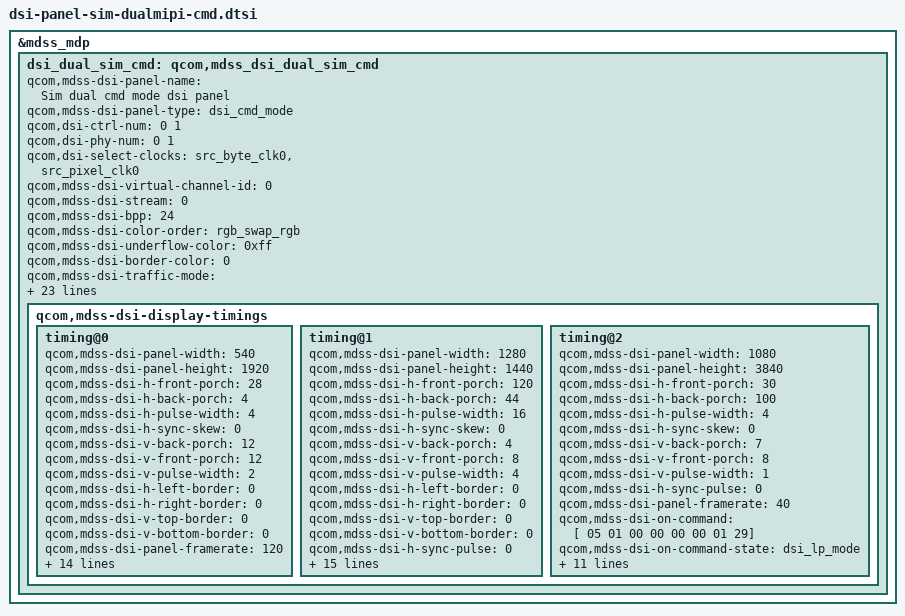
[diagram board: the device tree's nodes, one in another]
&mdss_mdp {
	dsi_dual_sim_cmd: qcom,mdss_dsi_dual_sim_cmd {
		qcom,mdss-dsi-panel-name = "Sim dual cmd mode dsi panel";
		qcom,mdss-dsi-panel-type = "dsi_cmd_mode";

		qcom,dsi-ctrl-num = <0 1>;
		qcom,dsi-phy-num = <0 1>;
		qcom,dsi-select-clocks = "src_byte_clk0", "src_pixel_clk0";

		qcom,mdss-dsi-virtual-channel-id = <0>;
		qcom,mdss-dsi-stream = <0>;
		qcom,mdss-dsi-bpp = <24>;
		qcom,mdss-dsi-color-order = "rgb_swap_rgb";
		qcom,mdss-dsi-underflow-color = <0xff>;
		qcom,mdss-dsi-border-color = <0>;
		qcom,mdss-dsi-traffic-mode = "non_burst_sync_event";
		qcom,mdss-dsi-bllp-eof-power-mode;
		qcom,mdss-dsi-bllp-power-mode;
		qcom,cmd-sync-wait-broadcast;
		qcom,mdss-dsi-lane-0-state;
		qcom,mdss-dsi-lane-1-state;
		qcom,mdss-dsi-lane-2-state;
		qcom,mdss-dsi-lane-3-state;
		qcom,mdss-dsi-hor-line-idle = <0 40 256>,
						<40 120 128>,
						<120 240 64>;
		qcom,mdss-dsi-reset-sequence = <1 10>, <0 10>, <1 10>;
		qcom,mdss-dsi-bl-max-level = <4095>;
		qcom,mdss-dsi-dma-trigger = "trigger_sw";
		qcom,mdss-dsi-mdp-trigger = "none";
		qcom,mdss-dsi-te-pin-select = <1>;
		qcom,mdss-dsi-wr-mem-start = <0x2c>;
		qcom,mdss-dsi-wr-mem-continue = <0x3c>;
		qcom,mdss-dsi-te-dcs-command = <1>;
		qcom,mdss-dsi-te-check-enable;
		qcom,mdss-dsi-te-using-wd;
		qcom,mdss-dsi-te-using-te-pin;
		qcom,panel-ack-disabled;
		qcom,mdss-dsi-qsync-min-refresh-rate = <45>;

		qcom,mdss-dsi-display-timings {
			timing@0 {
				qcom,mdss-dsi-panel-width = <540>;
				qcom,mdss-dsi-panel-height = <1920>;
				qcom,mdss-dsi-h-front-porch = <28>;
				qcom,mdss-dsi-h-back-porch = <4>;
				qcom,mdss-dsi-h-pulse-width = <4>;
				qcom,mdss-dsi-h-sync-skew = <0>;
				qcom,mdss-dsi-v-back-porch = <12>;
				qcom,mdss-dsi-v-front-porch = <12>;
				qcom,mdss-dsi-v-pulse-width = <2>;
				qcom,mdss-dsi-h-left-border = <0>;
				qcom,mdss-dsi-h-right-border = <0>;
				qcom,mdss-dsi-v-top-border = <0>;
				qcom,mdss-dsi-v-bottom-border = <0>;
				qcom,mdss-dsi-panel-framerate = <120>;
				qcom,mdss-dsi-on-command =
					[/* exit sleep mode, wait 0ms */
					05 01 00 00 00 00 01 29];
					/* Set display on, wait 16ms */
				qcom,mdss-dsi-on-command-state = "dsi_lp_mode";
				qcom,mdss-dsi-off-command =
					[05 01 00 00 00 00 02 28 00
					05 01 00 00 00 00 02 10 00];
				qcom,mdss-dsi-off-command-state = "dsi_hs_mode";
				qcom,mdss-dsi-qsync-on-commands =
					[15 01 00 00 00 00 02 51 00];
				qcom,mdss-dsi-qsync-on-commands-state =
					"dsi_hs_mode";
				qcom,mdss-dsi-qsync-off-commands =
					[15 01 00 00 00 00 02 51 00];
				qcom,mdss-dsi-qsync-off-commands-state =
					"dsi_hs_mode";
			};

			timing@1 {
				qcom,mdss-dsi-panel-width = <1280>;
				qcom,mdss-dsi-panel-height = <1440>;
				qcom,mdss-dsi-h-front-porch = <120>;
				qcom,mdss-dsi-h-back-porch = <44>;
				qcom,mdss-dsi-h-pulse-width = <16>;
				qcom,mdss-dsi-h-sync-skew = <0>;
				qcom,mdss-dsi-v-back-porch = <4>;
				qcom,mdss-dsi-v-front-porch = <8>;
				qcom,mdss-dsi-v-pulse-width = <4>;
				qcom,mdss-dsi-h-left-border = <0>;
				qcom,mdss-dsi-h-right-border = <0>;
				qcom,mdss-dsi-v-top-border = <0>;
				qcom,mdss-dsi-v-bottom-border = <0>;
				qcom,mdss-dsi-h-sync-pulse = <0>;
				qcom,mdss-dsi-panel-framerate = <60>;
				qcom,mdss-dsi-on-command =
					[/* exit sleep mode, wait 0ms */
					05 01 00 00 00 00 01 29];
				qcom,mdss-dsi-on-command-state = "dsi_lp_mode";
				qcom,mdss-dsi-off-command =
					[05 01 00 00 00 00 02 28 00
					05 01 00 00 00 00 02 10 00];
				qcom,mdss-dsi-off-command-state = "dsi_hs_mode";
				qcom,mdss-dsi-qsync-on-commands =
					[15 01 00 00 00 00 02 51 00];
				qcom,mdss-dsi-qsync-on-commands-state =
					"dsi_hs_mode";
				qcom,mdss-dsi-qsync-off-commands =
					[15 01 00 00 00 00 02 51 00];
				qcom,mdss-dsi-qsync-off-commands-state =
					"dsi_hs_mode";
			};

			timing@2 {
				qcom,mdss-dsi-panel-width = <1080>;
				qcom,mdss-dsi-panel-height = <3840>;
				qcom,mdss-dsi-h-front-porch = <30>;
				qcom,mdss-dsi-h-back-porch = <100>;
				qcom,mdss-dsi-h-pulse-width = <4>;
				qcom,mdss-dsi-h-sync-skew = <0>;
				qcom,mdss-dsi-v-back-porch = <7>;
				qcom,mdss-dsi-v-front-porch = <8>;
				qcom,mdss-dsi-v-pulse-width = <1>;
				qcom,mdss-dsi-h-sync-pulse = <0>;
				qcom,mdss-dsi-panel-framerate = <40>;
				qcom,mdss-dsi-on-command =
					[/* exit sleep mode, wait 0ms */
					05 01 00 00 00 00 01 29];
				qcom,mdss-dsi-on-command-state = "dsi_lp_mode";
				qcom,mdss-dsi-off-command =
					[05 01 00 00 00 00 02 28 00
					05 01 00 00 00 00 02 10 00];
				qcom,mdss-dsi-off-command-state = "dsi_hs_mode";
				qcom,mdss-dsi-qsync-on-commands =
					[15 01 00 00 00 00 02 51 00];
				qcom,mdss-dsi-qsync-on-commands-state =
					"dsi_hs_mode";
				qcom,mdss-dsi-qsync-off-commands =
					[15 01 00 00 00 00 02 51 00];
				qcom,mdss-dsi-qsync-off-commands-state =
					"dsi_hs_mode";
			};
		};
	};
};
